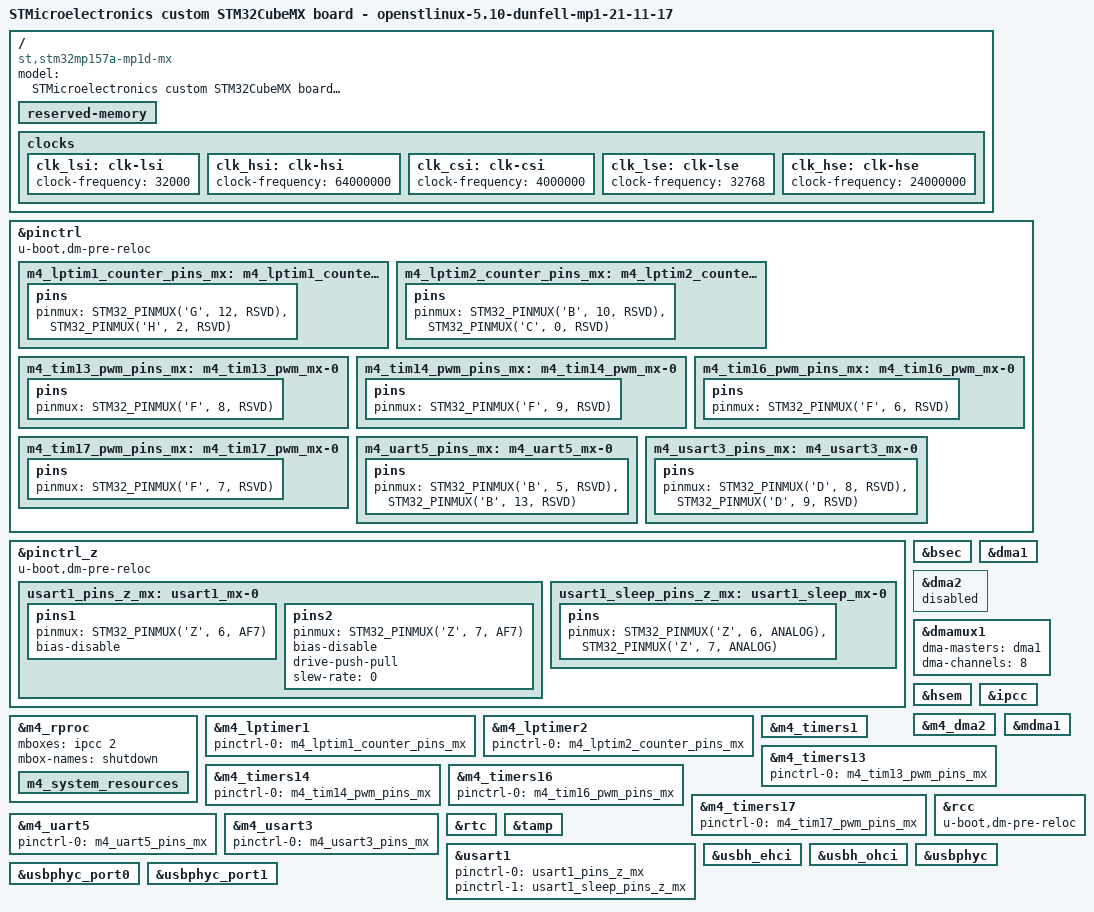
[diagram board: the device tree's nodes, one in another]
/* SPDX-License-Identifier: (GPL-2.0+ OR BSD-3-Clause) */
/*
 * Copyright (C) STMicroelectronics 2022 - All Rights Reserved
 * Author: STM32CubeMX code generation for STMicroelectronics.
 */

/* For more information on Device Tree configuration, please refer to
 * https://wiki.st.com/stm32mpu/wiki/Category:Device_tree_configuration
 */

/dts-v1/;
#include <dt-bindings/pinctrl/stm32-pinfunc.h>

#include "stm32mp157.dtsi"
#include "stm32mp15xa.dtsi"
#include "stm32mp15xxac-pinctrl.dtsi"
#include "stm32mp15-m4-srm.dtsi"

/* USER CODE BEGIN includes */
/* USER CODE END includes */

/ {
	model = "STMicroelectronics custom STM32CubeMX board - openstlinux-5.10-dunfell-mp1-21-11-17";
	compatible = "st,stm32mp157a-mp1d-mx", "st,stm32mp157";

	/* !!! log : Warning - no DDR config found: 'memory' node not generated  !!! */

	/*
	memory@??? {
		reg = < ??? >;
	};
	*/

	reserved-memory {
		#address-cells = <1>;
		#size-cells = <1>;
		ranges;

		/* USER CODE BEGIN reserved-memory */
		/* USER CODE END reserved-memory */
	};

	/* USER CODE BEGIN root */
	/* USER CODE END root */

	clocks {
		/* USER CODE BEGIN clocks */
		/* USER CODE END clocks */

#ifndef CONFIG_TFABOOT
		clk_lsi: clk-lsi {
			clock-frequency = <32000>;
		};
		clk_hsi: clk-hsi {
			clock-frequency = <64000000>;
		};
		clk_csi: clk-csi {
			clock-frequency = <4000000>;
		};
		clk_lse: clk-lse {
			clock-frequency = <32768>;
		};
		clk_hse: clk-hse {
			clock-frequency = <24000000>;
		};
#endif	/*CONFIG_TFABOOT*/
	};

}; /*root*/

&pinctrl {
	u-boot,dm-pre-reloc;

	m4_lptim1_counter_pins_mx: m4_lptim1_counter_mx-0 {
		pins {
			pinmux = <STM32_PINMUX('G', 12, RSVD)>, /* LPTIM1_IN1 */
					 <STM32_PINMUX('H', 2, RSVD)>; /* LPTIM1_IN2 */
		};
	};

	m4_lptim2_counter_pins_mx: m4_lptim2_counter_mx-0 {
		pins {
			pinmux = <STM32_PINMUX('B', 10, RSVD)>, /* LPTIM2_IN1 */
					 <STM32_PINMUX('C', 0, RSVD)>; /* LPTIM2_IN2 */
		};
	};

	m4_tim13_pwm_pins_mx: m4_tim13_pwm_mx-0 {
		pins {
			pinmux = <STM32_PINMUX('F', 8, RSVD)>; /* TIM13_CH1 */
		};
	};

	m4_tim14_pwm_pins_mx: m4_tim14_pwm_mx-0 {
		pins {
			pinmux = <STM32_PINMUX('F', 9, RSVD)>; /* TIM14_CH1 */
		};
	};

	m4_tim16_pwm_pins_mx: m4_tim16_pwm_mx-0 {
		pins {
			pinmux = <STM32_PINMUX('F', 6, RSVD)>; /* TIM16_CH1 */
		};
	};

	m4_tim17_pwm_pins_mx: m4_tim17_pwm_mx-0 {
		pins {
			pinmux = <STM32_PINMUX('F', 7, RSVD)>; /* TIM17_CH1 */
		};
	};

	m4_uart5_pins_mx: m4_uart5_mx-0 {
		pins {
			pinmux = <STM32_PINMUX('B', 5, RSVD)>, /* UART5_RX */
					 <STM32_PINMUX('B', 13, RSVD)>; /* UART5_TX */
		};
	};

	m4_usart3_pins_mx: m4_usart3_mx-0 {
		pins {
			pinmux = <STM32_PINMUX('D', 8, RSVD)>, /* USART3_TX */
					 <STM32_PINMUX('D', 9, RSVD)>; /* USART3_RX */
		};
	};

	/* USER CODE BEGIN pinctrl */
	/* USER CODE END pinctrl */
};

&pinctrl_z {
	u-boot,dm-pre-reloc;

	usart1_pins_z_mx: usart1_mx-0 {
		pins1 {
			pinmux = <STM32_PINMUX('Z', 6, AF7)>; /* USART1_RX */
			bias-disable;
		};
		pins2 {
			pinmux = <STM32_PINMUX('Z', 7, AF7)>; /* USART1_TX */
			bias-disable;
			drive-push-pull;
			slew-rate = <0>;
		};
	};

	usart1_sleep_pins_z_mx: usart1_sleep_mx-0 {
		pins {
			pinmux = <STM32_PINMUX('Z', 6, ANALOG)>, /* USART1_RX */
					 <STM32_PINMUX('Z', 7, ANALOG)>; /* USART1_TX */
		};
	};

	/* USER CODE BEGIN pinctrl_z */
	/* USER CODE END pinctrl_z */
};

&m4_rproc{
	/*Restriction: "memory-region" property is not managed - please to use User-Section if needed*/
	mboxes = <&ipcc 2>;
	mbox-names = "shutdown";
	status = "okay";

	/* USER CODE BEGIN m4_rproc */
	/* USER CODE END m4_rproc */

	m4_system_resources{
		status = "okay";

		/* USER CODE BEGIN m4_system_resources */
		/* USER CODE END m4_system_resources */
	};
};

&bsec{
	status = "okay";

	/* USER CODE BEGIN bsec */
	/* USER CODE END bsec */
};

&dma1{
	status = "okay";

	/* USER CODE BEGIN dma1 */
	/* USER CODE END dma1 */
};

&dma2{
	status = "disabled";

	/* USER CODE BEGIN dma2 */
	/* USER CODE END dma2 */
};

&dmamux1{
	status = "okay";

	dma-masters = <&dma1>;
	dma-channels = <8>;

	/* USER CODE BEGIN dmamux1 */
	/* USER CODE END dmamux1 */
};

&hsem{
	status = "okay";

	/* USER CODE BEGIN hsem */
	/* USER CODE END hsem */
};

&ipcc{
	status = "okay";

	/* USER CODE BEGIN ipcc */
	/* USER CODE END ipcc */
};

&m4_dma2{
	status = "okay";

	/* USER CODE BEGIN m4_dma2 */
	/* USER CODE END m4_dma2 */
};

&m4_lptimer1{
	pinctrl-names = "default";
	pinctrl-0 = <&m4_lptim1_counter_pins_mx>;
	status = "okay";

	/* USER CODE BEGIN m4_lptimer1 */
	/* USER CODE END m4_lptimer1 */
};

&m4_lptimer2{
	pinctrl-names = "default";
	pinctrl-0 = <&m4_lptim2_counter_pins_mx>;
	status = "okay";

	/* USER CODE BEGIN m4_lptimer2 */
	/* USER CODE END m4_lptimer2 */
};

&m4_timers1{
	status = "okay";

	/* USER CODE BEGIN m4_timers1 */
	/* USER CODE END m4_timers1 */
};

&m4_timers13{
	pinctrl-names = "default";
	pinctrl-0 = <&m4_tim13_pwm_pins_mx>;
	status = "okay";

	/* USER CODE BEGIN m4_timers13 */
	/* USER CODE END m4_timers13 */
};

&m4_timers14{
	pinctrl-names = "default";
	pinctrl-0 = <&m4_tim14_pwm_pins_mx>;
	status = "okay";

	/* USER CODE BEGIN m4_timers14 */
	/* USER CODE END m4_timers14 */
};

&m4_timers16{
	pinctrl-names = "default";
	pinctrl-0 = <&m4_tim16_pwm_pins_mx>;
	status = "okay";

	/* USER CODE BEGIN m4_timers16 */
	/* USER CODE END m4_timers16 */
};

&m4_timers17{
	pinctrl-names = "default";
	pinctrl-0 = <&m4_tim17_pwm_pins_mx>;
	status = "okay";

	/* USER CODE BEGIN m4_timers17 */
	/* USER CODE END m4_timers17 */
};

&m4_uart5{
	pinctrl-names = "default";
	pinctrl-0 = <&m4_uart5_pins_mx>;
	status = "okay";

	/* USER CODE BEGIN m4_uart5 */
	/* USER CODE END m4_uart5 */
};

&m4_usart3{
	pinctrl-names = "default";
	pinctrl-0 = <&m4_usart3_pins_mx>;
	status = "okay";

	/* USER CODE BEGIN m4_usart3 */
	/* USER CODE END m4_usart3 */
};

&mdma1{
	status = "okay";

	/* USER CODE BEGIN mdma1 */
	/* USER CODE END mdma1 */
};

&rcc{
	u-boot,dm-pre-reloc;
	status = "okay";

	/* USER CODE BEGIN rcc */
	/* USER CODE END rcc */
};

&rtc{
	status = "okay";

	/* USER CODE BEGIN rtc */
	/* USER CODE END rtc */
};

&tamp{
	status = "okay";

	/* USER CODE BEGIN tamp */
	/* USER CODE END tamp */
};

&usart1{
	pinctrl-names = "default", "sleep";
	pinctrl-0 = <&usart1_pins_z_mx>;
	pinctrl-1 = <&usart1_sleep_pins_z_mx>;
	status = "okay";

	/* USER CODE BEGIN usart1 */
	/* USER CODE END usart1 */
};

&usbh_ehci{
	status = "okay";

	/* USER CODE BEGIN usbh_ehci */
	/* USER CODE END usbh_ehci */
};

&usbh_ohci{
	status = "okay";

	/* USER CODE BEGIN usbh_ohci */
	/* USER CODE END usbh_ohci */
};

&usbphyc{
	status = "okay";

	/* USER CODE BEGIN usbphyc */
	/* USER CODE END usbphyc */
};

&usbphyc_port0{
	status = "okay";

	/* USER CODE BEGIN usbphyc_port0 */
	/* USER CODE END usbphyc_port0 */
};

&usbphyc_port1{
	status = "okay";

	/* USER CODE BEGIN usbphyc_port1 */
	/* USER CODE END usbphyc_port1 */
};

/* USER CODE BEGIN addons */
/* USER CODE END addons */

